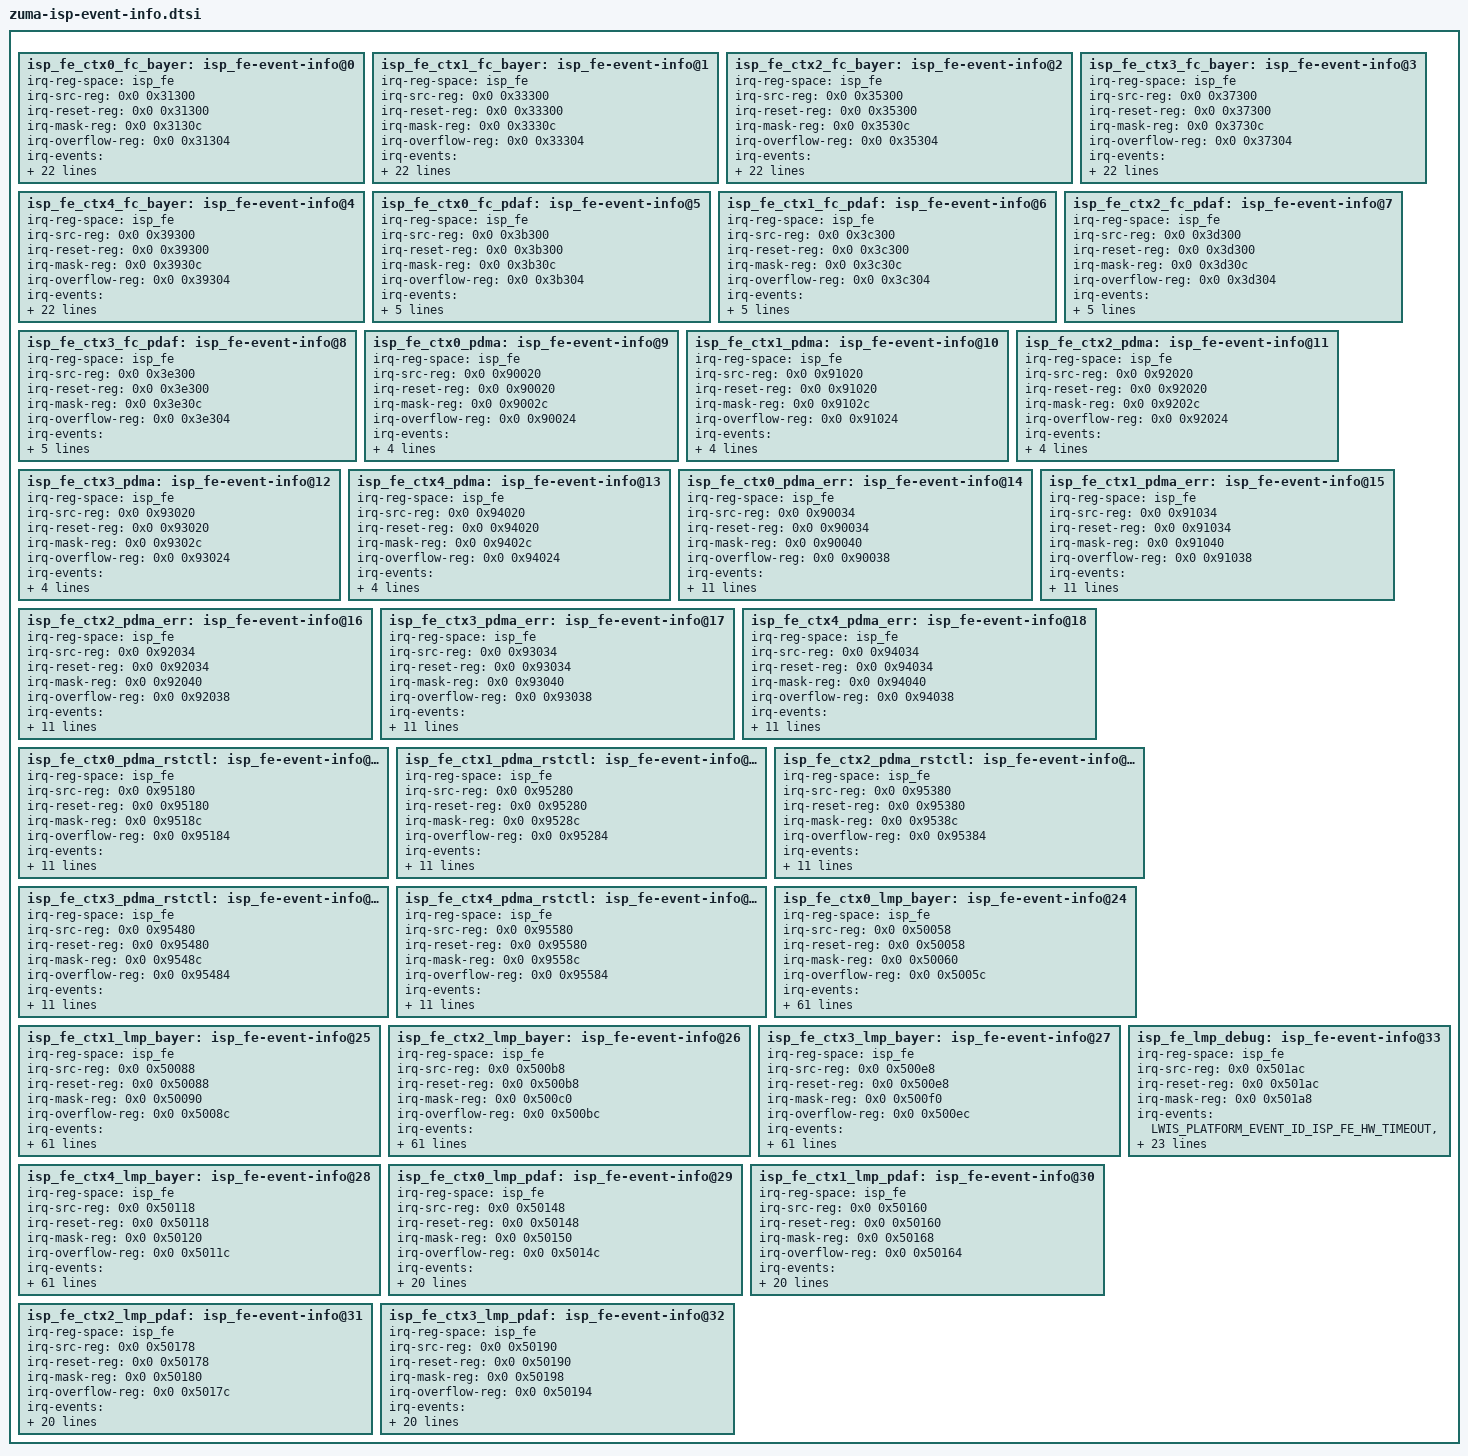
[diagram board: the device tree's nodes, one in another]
// SPDX-License-Identifier: GPL-2.0-only
/*
 * Google ZUMA ISP device tree for interrupt events
 *
 * Copyright 2022 Google LLC.
 */

#include <dt-bindings/lwis/platform/zuma/fc.h>
{
	/* FC bayer pipeline interrupt event definitions */
	isp_fe_ctx0_fc_bayer: isp_fe-event-info@0 {
		irq-reg-space = "isp_fe";
		irq-src-reg = <0x0 0x31300>;
		irq-reset-reg = <0x0 0x31300>;
		irq-mask-reg = <0x0 0x3130c>;
		irq-overflow-reg = <0x0 0x31304>;

		irq-events =
			<LWIS_PLATFORM_EVENT_ID_ISP_FE_CTX0_FC_SOF>,
			<LWIS_PLATFORM_EVENT_ID_ISP_FE_CTX0_FC_EOF>,
			<LWIS_PLATFORM_EVENT_ID_ISP_FE_CTX0_FC_REG_UPDATED>,
			<LWIS_PLATFORM_EVENT_ID_ISP_FE_CTX0_FC_ABORT_START>,
			<LWIS_PLATFORM_EVENT_ID_ISP_FE_CTX0_FC_ABORT_DMA_CMPLT>,
			<LWIS_PLATFORM_EVENT_ID_ISP_FE_CTX0_FC_ABORT_DONE>,
			<LWIS_PLATFORM_EVENT_ID_ISP_FE_CTX0_FC_LATE_CONFIG>,
			<LWIS_PLATFORM_EVENT_ID_ISP_FE_CTX0_FC_ERROR>,
			<LWIS_PLATFORM_EVENT_ID_ISP_FE_CTX0_SPD_WDMA_BUS_ERROR>,
			<LWIS_PLATFORM_EVENT_ID_ISP_FE_CTX0_LMP_IDMA0_BUS_ERROR>,
			<LWIS_PLATFORM_EVENT_ID_ISP_FE_CTX0_LMP_IDMA1_BUS_ERROR>;
		int-reg-bits =
			<ISP_FE_FC_BAYER_CTX0_FC_SOF>,
			<ISP_FE_FC_BAYER_CTX0_FC_EOF>,
			<ISP_FE_FC_BAYER_CTX0_FC_REG_UPDATED>,
			<ISP_FE_FC_BAYER_CTX0_FC_ABORT_START>,
			<ISP_FE_FC_BAYER_CTX0_FC_ABORT_DMA_CMPLT>,
			<ISP_FE_FC_BAYER_CTX0_FC_ABORT_DONE>,
			<ISP_FE_FC_BAYER_CTX0_FC_LATE_CONFIG>,
			<ISP_FE_FC_BAYER_CTX0_FC_ERROR>,
			<ISP_FE_FC_BAYER_CTX0_SPD_WDMA_BUS_ERROR>,
			<ISP_FE_FC_BAYER_CTX0_LMP_IDMA0_BUS_ERROR>,
			<ISP_FE_FC_BAYER_CTX0_LMP_IDMA1_BUS_ERROR>;
	};
	isp_fe_ctx1_fc_bayer: isp_fe-event-info@1 {
		irq-reg-space = "isp_fe";
		irq-src-reg = <0x0 0x33300>;
		irq-reset-reg = <0x0 0x33300>;
		irq-mask-reg = <0x0 0x3330c>;
		irq-overflow-reg = <0x0 0x33304>;

		irq-events =
			<LWIS_PLATFORM_EVENT_ID_ISP_FE_CTX1_FC_SOF>,
			<LWIS_PLATFORM_EVENT_ID_ISP_FE_CTX1_FC_EOF>,
			<LWIS_PLATFORM_EVENT_ID_ISP_FE_CTX1_FC_REG_UPDATED>,
			<LWIS_PLATFORM_EVENT_ID_ISP_FE_CTX1_FC_ABORT_START>,
			<LWIS_PLATFORM_EVENT_ID_ISP_FE_CTX1_FC_ABORT_DMA_CMPLT>,
			<LWIS_PLATFORM_EVENT_ID_ISP_FE_CTX1_FC_ABORT_DONE>,
			<LWIS_PLATFORM_EVENT_ID_ISP_FE_CTX1_FC_LATE_CONFIG>,
			<LWIS_PLATFORM_EVENT_ID_ISP_FE_CTX1_FC_ERROR>,
			<LWIS_PLATFORM_EVENT_ID_ISP_FE_CTX1_SPD_WDMA_BUS_ERROR>,
			<LWIS_PLATFORM_EVENT_ID_ISP_FE_CTX1_LMP_IDMA0_BUS_ERROR>,
			<LWIS_PLATFORM_EVENT_ID_ISP_FE_CTX1_LMP_IDMA1_BUS_ERROR>;
		int-reg-bits =
			<ISP_FE_FC_BAYER_CTX1_FC_SOF>,
			<ISP_FE_FC_BAYER_CTX1_FC_EOF>,
			<ISP_FE_FC_BAYER_CTX1_FC_REG_UPDATED>,
			<ISP_FE_FC_BAYER_CTX1_FC_ABORT_START>,
			<ISP_FE_FC_BAYER_CTX1_FC_ABORT_DMA_CMPLT>,
			<ISP_FE_FC_BAYER_CTX1_FC_ABORT_DONE>,
			<ISP_FE_FC_BAYER_CTX1_FC_LATE_CONFIG>,
			<ISP_FE_FC_BAYER_CTX1_FC_ERROR>,
			<ISP_FE_FC_BAYER_CTX1_SPD_WDMA_BUS_ERROR>,
			<ISP_FE_FC_BAYER_CTX1_LMP_IDMA0_BUS_ERROR>,
			<ISP_FE_FC_BAYER_CTX1_LMP_IDMA1_BUS_ERROR>;
	};
	isp_fe_ctx2_fc_bayer: isp_fe-event-info@2 {
		irq-reg-space = "isp_fe";
		irq-src-reg = <0x0 0x35300>;
		irq-reset-reg = <0x0 0x35300>;
		irq-mask-reg = <0x0 0x3530c>;
		irq-overflow-reg = <0x0 0x35304>;

		irq-events =
			<LWIS_PLATFORM_EVENT_ID_ISP_FE_CTX2_FC_SOF>,
			<LWIS_PLATFORM_EVENT_ID_ISP_FE_CTX2_FC_EOF>,
			<LWIS_PLATFORM_EVENT_ID_ISP_FE_CTX2_FC_REG_UPDATED>,
			<LWIS_PLATFORM_EVENT_ID_ISP_FE_CTX2_FC_ABORT_START>,
			<LWIS_PLATFORM_EVENT_ID_ISP_FE_CTX2_FC_ABORT_DMA_CMPLT>,
			<LWIS_PLATFORM_EVENT_ID_ISP_FE_CTX2_FC_ABORT_DONE>,
			<LWIS_PLATFORM_EVENT_ID_ISP_FE_CTX2_FC_LATE_CONFIG>,
			<LWIS_PLATFORM_EVENT_ID_ISP_FE_CTX2_FC_ERROR>,
			<LWIS_PLATFORM_EVENT_ID_ISP_FE_CTX2_SPD_WDMA_BUS_ERROR>,
			<LWIS_PLATFORM_EVENT_ID_ISP_FE_CTX2_LMP_IDMA0_BUS_ERROR>,
			<LWIS_PLATFORM_EVENT_ID_ISP_FE_CTX2_LMP_IDMA1_BUS_ERROR>;
		int-reg-bits =
			<ISP_FE_FC_BAYER_CTX2_FC_SOF>,
			<ISP_FE_FC_BAYER_CTX2_FC_EOF>,
			<ISP_FE_FC_BAYER_CTX2_FC_REG_UPDATED>,
			<ISP_FE_FC_BAYER_CTX2_FC_ABORT_START>,
			<ISP_FE_FC_BAYER_CTX2_FC_ABORT_DMA_CMPLT>,
			<ISP_FE_FC_BAYER_CTX2_FC_ABORT_DONE>,
			<ISP_FE_FC_BAYER_CTX2_FC_LATE_CONFIG>,
			<ISP_FE_FC_BAYER_CTX2_FC_ERROR>,
			<ISP_FE_FC_BAYER_CTX2_SPD_WDMA_BUS_ERROR>,
			<ISP_FE_FC_BAYER_CTX2_LMP_IDMA0_BUS_ERROR>,
			<ISP_FE_FC_BAYER_CTX2_LMP_IDMA1_BUS_ERROR>;
	};
	isp_fe_ctx3_fc_bayer: isp_fe-event-info@3 {
		irq-reg-space = "isp_fe";
		irq-src-reg = <0x0 0x37300>;
		irq-reset-reg = <0x0 0x37300>;
		irq-mask-reg = <0x0 0x3730c>;
		irq-overflow-reg = <0x0 0x37304>;

		irq-events =
			<LWIS_PLATFORM_EVENT_ID_ISP_FE_CTX3_FC_SOF>,
			<LWIS_PLATFORM_EVENT_ID_ISP_FE_CTX3_FC_EOF>,
			<LWIS_PLATFORM_EVENT_ID_ISP_FE_CTX3_FC_REG_UPDATED>,
			<LWIS_PLATFORM_EVENT_ID_ISP_FE_CTX3_FC_ABORT_START>,
			<LWIS_PLATFORM_EVENT_ID_ISP_FE_CTX3_FC_ABORT_DMA_CMPLT>,
			<LWIS_PLATFORM_EVENT_ID_ISP_FE_CTX3_FC_ABORT_DONE>,
			<LWIS_PLATFORM_EVENT_ID_ISP_FE_CTX3_FC_LATE_CONFIG>,
			<LWIS_PLATFORM_EVENT_ID_ISP_FE_CTX3_FC_ERROR>,
			<LWIS_PLATFORM_EVENT_ID_ISP_FE_CTX3_SPD_WDMA_BUS_ERROR>,
			<LWIS_PLATFORM_EVENT_ID_ISP_FE_CTX3_LMP_IDMA0_BUS_ERROR>,
			<LWIS_PLATFORM_EVENT_ID_ISP_FE_CTX3_LMP_IDMA1_BUS_ERROR>;
		int-reg-bits =
			<ISP_FE_FC_BAYER_CTX3_FC_SOF>,
			<ISP_FE_FC_BAYER_CTX3_FC_EOF>,
			<ISP_FE_FC_BAYER_CTX3_FC_REG_UPDATED>,
			<ISP_FE_FC_BAYER_CTX3_FC_ABORT_START>,
			<ISP_FE_FC_BAYER_CTX3_FC_ABORT_DMA_CMPLT>,
			<ISP_FE_FC_BAYER_CTX3_FC_ABORT_DONE>,
			<ISP_FE_FC_BAYER_CTX3_FC_LATE_CONFIG>,
			<ISP_FE_FC_BAYER_CTX3_FC_ERROR>,
			<ISP_FE_FC_BAYER_CTX3_SPD_WDMA_BUS_ERROR>,
			<ISP_FE_FC_BAYER_CTX3_LMP_IDMA0_BUS_ERROR>,
			<ISP_FE_FC_BAYER_CTX3_LMP_IDMA1_BUS_ERROR>;
	};
	isp_fe_ctx4_fc_bayer: isp_fe-event-info@4 {
		irq-reg-space = "isp_fe";
		irq-src-reg = <0x0 0x39300>;
		irq-reset-reg = <0x0 0x39300>;
		irq-mask-reg = <0x0 0x3930c>;
		irq-overflow-reg = <0x0 0x39304>;

		irq-events =
			<LWIS_PLATFORM_EVENT_ID_ISP_FE_CTX4_FC_SOF>,
			<LWIS_PLATFORM_EVENT_ID_ISP_FE_CTX4_FC_EOF>,
			<LWIS_PLATFORM_EVENT_ID_ISP_FE_CTX4_FC_REG_UPDATED>,
			<LWIS_PLATFORM_EVENT_ID_ISP_FE_CTX4_FC_ABORT_START>,
			<LWIS_PLATFORM_EVENT_ID_ISP_FE_CTX4_FC_ABORT_DMA_CMPLT>,
			<LWIS_PLATFORM_EVENT_ID_ISP_FE_CTX4_FC_ABORT_DONE>,
			<LWIS_PLATFORM_EVENT_ID_ISP_FE_CTX4_FC_LATE_CONFIG>,
			<LWIS_PLATFORM_EVENT_ID_ISP_FE_CTX4_FC_ERROR>,
			<LWIS_PLATFORM_EVENT_ID_ISP_FE_CTX4_SPD_WDMA_BUS_ERROR>,
			<LWIS_PLATFORM_EVENT_ID_ISP_FE_CTX4_LMP_IDMA0_BUS_ERROR>,
			<LWIS_PLATFORM_EVENT_ID_ISP_FE_CTX4_LMP_IDMA1_BUS_ERROR>;
		int-reg-bits =
			<ISP_FE_FC_BAYER_CTX4_FC_SOF>,
			<ISP_FE_FC_BAYER_CTX4_FC_EOF>,
			<ISP_FE_FC_BAYER_CTX4_FC_REG_UPDATED>,
			<ISP_FE_FC_BAYER_CTX4_FC_ABORT_START>,
			<ISP_FE_FC_BAYER_CTX4_FC_ABORT_DMA_CMPLT>,
			<ISP_FE_FC_BAYER_CTX4_FC_ABORT_DONE>,
			<ISP_FE_FC_BAYER_CTX4_FC_LATE_CONFIG>,
			<ISP_FE_FC_BAYER_CTX4_FC_ERROR>,
			<ISP_FE_FC_BAYER_CTX4_SPD_WDMA_BUS_ERROR>,
			<ISP_FE_FC_BAYER_CTX4_LMP_IDMA0_BUS_ERROR>,
			<ISP_FE_FC_BAYER_CTX4_LMP_IDMA1_BUS_ERROR>;
	};
	/* FC pdaf pipeline interrupt event definitions */
	isp_fe_ctx0_fc_pdaf: isp_fe-event-info@5 {
		irq-reg-space = "isp_fe";
		irq-src-reg = <0x0 0x3b300>;
		irq-reset-reg = <0x0 0x3b300>;
		irq-mask-reg = <0x0 0x3b30c>;
		irq-overflow-reg = <0x0 0x3b304>;

		irq-events =
			<LWIS_PLATFORM_EVENT_ID_ISP_FE_CTX0_PDAF_LATE_CONFIG>,
			<LWIS_PLATFORM_EVENT_ID_ISP_FE_CTX0_PDAF_ERROR>;
		int-reg-bits =
			<ISP_FE_FC_PDAF_CTX0_PDAF_LATE_CONFIG>,
			<ISP_FE_FC_PDAF_CTX0_PDAF_ERROR>;
	};
	isp_fe_ctx1_fc_pdaf: isp_fe-event-info@6 {
		irq-reg-space = "isp_fe";
		irq-src-reg = <0x0 0x3c300>;
		irq-reset-reg = <0x0 0x3c300>;
		irq-mask-reg = <0x0 0x3c30c>;
		irq-overflow-reg = <0x0 0x3c304>;

		irq-events =
			<LWIS_PLATFORM_EVENT_ID_ISP_FE_CTX1_PDAF_LATE_CONFIG>,
			<LWIS_PLATFORM_EVENT_ID_ISP_FE_CTX1_PDAF_ERROR>;
		int-reg-bits =
			<ISP_FE_FC_PDAF_CTX1_PDAF_LATE_CONFIG>,
			<ISP_FE_FC_PDAF_CTX1_PDAF_ERROR>;
	};
	isp_fe_ctx2_fc_pdaf: isp_fe-event-info@7 {
		irq-reg-space = "isp_fe";
		irq-src-reg = <0x0 0x3d300>;
		irq-reset-reg = <0x0 0x3d300>;
		irq-mask-reg = <0x0 0x3d30c>;
		irq-overflow-reg = <0x0 0x3d304>;

		irq-events =
			<LWIS_PLATFORM_EVENT_ID_ISP_FE_CTX2_PDAF_LATE_CONFIG>,
			<LWIS_PLATFORM_EVENT_ID_ISP_FE_CTX2_PDAF_ERROR>;
		int-reg-bits =
			<ISP_FE_FC_PDAF_CTX2_PDAF_LATE_CONFIG>,
			<ISP_FE_FC_PDAF_CTX2_PDAF_ERROR>;
	};
	isp_fe_ctx3_fc_pdaf: isp_fe-event-info@8 {
		irq-reg-space = "isp_fe";
		irq-src-reg = <0x0 0x3e300>;
		irq-reset-reg = <0x0 0x3e300>;
		irq-mask-reg = <0x0 0x3e30c>;
		irq-overflow-reg = <0x0 0x3e304>;

		irq-events =
			<LWIS_PLATFORM_EVENT_ID_ISP_FE_CTX3_PDAF_LATE_CONFIG>,
			<LWIS_PLATFORM_EVENT_ID_ISP_FE_CTX3_PDAF_ERROR>;
		int-reg-bits =
			<ISP_FE_FC_PDAF_CTX3_PDAF_LATE_CONFIG>,
			<ISP_FE_FC_PDAF_CTX3_PDAF_ERROR>;
	};
	/* PDMA interrupt event definitions */
	isp_fe_ctx0_pdma: isp_fe-event-info@9 {
		irq-reg-space = "isp_fe";
		irq-src-reg = <0x0 0x90020>;
		irq-reset-reg = <0x0 0x90020>;
		irq-mask-reg = <0x0 0x9002c>;
		irq-overflow-reg = <0x0 0x90024>;

		irq-events =
			<LWIS_PLATFORM_EVENT_ID_ISP_FE_CTX0_IRQ_CMD>,
			<LWIS_PLATFORM_EVENT_ID_ISP_FE_CTX0_ALMOST_EMPTY>;
		int-reg-bits =
			<ISP_FE_PDMA_CTX0_IRQ_CMD>,
			<ISP_FE_PDMA_CTX0_ALMOST_EMPTY>;
	};
	isp_fe_ctx1_pdma: isp_fe-event-info@10 {
		irq-reg-space = "isp_fe";
		irq-src-reg = <0x0 0x91020>;
		irq-reset-reg = <0x0 0x91020>;
		irq-mask-reg = <0x0 0x9102c>;
		irq-overflow-reg = <0x0 0x91024>;

		irq-events =
			<LWIS_PLATFORM_EVENT_ID_ISP_FE_CTX1_IRQ_CMD>,
			<LWIS_PLATFORM_EVENT_ID_ISP_FE_CTX1_ALMOST_EMPTY>;
		int-reg-bits =
			<ISP_FE_PDMA_CTX1_IRQ_CMD>,
			<ISP_FE_PDMA_CTX1_ALMOST_EMPTY>;
	};
	isp_fe_ctx2_pdma: isp_fe-event-info@11 {
		irq-reg-space = "isp_fe";
		irq-src-reg = <0x0 0x92020>;
		irq-reset-reg = <0x0 0x92020>;
		irq-mask-reg = <0x0 0x9202c>;
		irq-overflow-reg = <0x0 0x92024>;

		irq-events =
			<LWIS_PLATFORM_EVENT_ID_ISP_FE_CTX2_IRQ_CMD>,
			<LWIS_PLATFORM_EVENT_ID_ISP_FE_CTX2_ALMOST_EMPTY>;
		int-reg-bits =
			<ISP_FE_PDMA_CTX2_IRQ_CMD>,
			<ISP_FE_PDMA_CTX2_ALMOST_EMPTY>;
	};
	isp_fe_ctx3_pdma: isp_fe-event-info@12 {
		irq-reg-space = "isp_fe";
		irq-src-reg = <0x0 0x93020>;
		irq-reset-reg = <0x0 0x93020>;
		irq-mask-reg = <0x0 0x9302c>;
		irq-overflow-reg = <0x0 0x93024>;

		irq-events =
			<LWIS_PLATFORM_EVENT_ID_ISP_FE_CTX3_IRQ_CMD>,
			<LWIS_PLATFORM_EVENT_ID_ISP_FE_CTX3_ALMOST_EMPTY>;
		int-reg-bits =
			<ISP_FE_PDMA_CTX3_IRQ_CMD>,
			<ISP_FE_PDMA_CTX3_ALMOST_EMPTY>;
	};
	isp_fe_ctx4_pdma: isp_fe-event-info@13 {
		irq-reg-space = "isp_fe";
		irq-src-reg = <0x0 0x94020>;
		irq-reset-reg = <0x0 0x94020>;
		irq-mask-reg = <0x0 0x9402c>;
		irq-overflow-reg = <0x0 0x94024>;

		irq-events =
			<LWIS_PLATFORM_EVENT_ID_ISP_FE_CTX4_IRQ_CMD>,
			<LWIS_PLATFORM_EVENT_ID_ISP_FE_CTX4_ALMOST_EMPTY>;
		int-reg-bits =
			<ISP_FE_PDMA_CTX4_IRQ_CMD>,
			<ISP_FE_PDMA_CTX4_ALMOST_EMPTY>;
	};
	/* PDMA error interrupt event definitions */
	isp_fe_ctx0_pdma_err: isp_fe-event-info@14 {
		irq-reg-space = "isp_fe";
		irq-src-reg = <0x0 0x90034>;
		irq-reset-reg = <0x0 0x90034>;
		irq-mask-reg = <0x0 0x90040>;
		irq-overflow-reg = <0x0 0x90038>;

		irq-events =
			<LWIS_PLATFORM_EVENT_ID_ISP_FE_CTX0_MEM_BUS_ERR>,
			<LWIS_PLATFORM_EVENT_ID_ISP_FE_CTX0_CSR_BUS_ERR>,
			<LWIS_PLATFORM_EVENT_ID_ISP_FE_CTX0_ILLEGAL_CMD>,
			<LWIS_PLATFORM_EVENT_ID_ISP_FE_CTX0_RECUR_INDIR_CMD>,
			<LWIS_PLATFORM_EVENT_ID_ISP_FE_CTX0_CMD_SIZE_MISMATCH>;
		int-reg-bits =
			<ISP_FE_PDMA_ERR_CTX0_MEM_BUS_ERR>,
			<ISP_FE_PDMA_ERR_CTX0_CSR_BUS_ERR>,
			<ISP_FE_PDMA_ERR_CTX0_ILLEGAL_CMD>,
			<ISP_FE_PDMA_ERR_CTX0_RECUR_INDIR_CMD>,
			<ISP_FE_PDMA_ERR_CTX0_CMD_SIZE_MISMATCH>;
	};
	isp_fe_ctx1_pdma_err: isp_fe-event-info@15 {
		irq-reg-space = "isp_fe";
		irq-src-reg = <0x0 0x91034>;
		irq-reset-reg = <0x0 0x91034>;
		irq-mask-reg = <0x0 0x91040>;
		irq-overflow-reg = <0x0 0x91038>;

		irq-events =
			<LWIS_PLATFORM_EVENT_ID_ISP_FE_CTX1_MEM_BUS_ERR>,
			<LWIS_PLATFORM_EVENT_ID_ISP_FE_CTX1_CSR_BUS_ERR>,
			<LWIS_PLATFORM_EVENT_ID_ISP_FE_CTX1_ILLEGAL_CMD>,
			<LWIS_PLATFORM_EVENT_ID_ISP_FE_CTX1_RECUR_INDIR_CMD>,
			<LWIS_PLATFORM_EVENT_ID_ISP_FE_CTX1_CMD_SIZE_MISMATCH>;
		int-reg-bits =
			<ISP_FE_PDMA_ERR_CTX1_MEM_BUS_ERR>,
			<ISP_FE_PDMA_ERR_CTX1_CSR_BUS_ERR>,
			<ISP_FE_PDMA_ERR_CTX1_ILLEGAL_CMD>,
			<ISP_FE_PDMA_ERR_CTX1_RECUR_INDIR_CMD>,
			<ISP_FE_PDMA_ERR_CTX1_CMD_SIZE_MISMATCH>;
	};
	isp_fe_ctx2_pdma_err: isp_fe-event-info@16 {
		irq-reg-space = "isp_fe";
		irq-src-reg = <0x0 0x92034>;
		irq-reset-reg = <0x0 0x92034>;
		irq-mask-reg = <0x0 0x92040>;
		irq-overflow-reg = <0x0 0x92038>;

		irq-events =
			<LWIS_PLATFORM_EVENT_ID_ISP_FE_CTX2_MEM_BUS_ERR>,
			<LWIS_PLATFORM_EVENT_ID_ISP_FE_CTX2_CSR_BUS_ERR>,
			<LWIS_PLATFORM_EVENT_ID_ISP_FE_CTX2_ILLEGAL_CMD>,
			<LWIS_PLATFORM_EVENT_ID_ISP_FE_CTX2_RECUR_INDIR_CMD>,
			<LWIS_PLATFORM_EVENT_ID_ISP_FE_CTX2_CMD_SIZE_MISMATCH>;
		int-reg-bits =
			<ISP_FE_PDMA_ERR_CTX2_MEM_BUS_ERR>,
			<ISP_FE_PDMA_ERR_CTX2_CSR_BUS_ERR>,
			<ISP_FE_PDMA_ERR_CTX2_ILLEGAL_CMD>,
			<ISP_FE_PDMA_ERR_CTX2_RECUR_INDIR_CMD>,
			<ISP_FE_PDMA_ERR_CTX2_CMD_SIZE_MISMATCH>;
	};
	isp_fe_ctx3_pdma_err: isp_fe-event-info@17 {
		irq-reg-space = "isp_fe";
		irq-src-reg = <0x0 0x93034>;
		irq-reset-reg = <0x0 0x93034>;
		irq-mask-reg = <0x0 0x93040>;
		irq-overflow-reg = <0x0 0x93038>;

		irq-events =
			<LWIS_PLATFORM_EVENT_ID_ISP_FE_CTX3_MEM_BUS_ERR>,
			<LWIS_PLATFORM_EVENT_ID_ISP_FE_CTX3_CSR_BUS_ERR>,
			<LWIS_PLATFORM_EVENT_ID_ISP_FE_CTX3_ILLEGAL_CMD>,
			<LWIS_PLATFORM_EVENT_ID_ISP_FE_CTX3_RECUR_INDIR_CMD>,
			<LWIS_PLATFORM_EVENT_ID_ISP_FE_CTX3_CMD_SIZE_MISMATCH>;
		int-reg-bits =
			<ISP_FE_PDMA_ERR_CTX3_MEM_BUS_ERR>,
			<ISP_FE_PDMA_ERR_CTX3_CSR_BUS_ERR>,
			<ISP_FE_PDMA_ERR_CTX3_ILLEGAL_CMD>,
			<ISP_FE_PDMA_ERR_CTX3_RECUR_INDIR_CMD>,
			<ISP_FE_PDMA_ERR_CTX3_CMD_SIZE_MISMATCH>;
	};
	isp_fe_ctx4_pdma_err: isp_fe-event-info@18 {
		irq-reg-space = "isp_fe";
		irq-src-reg = <0x0 0x94034>;
		irq-reset-reg = <0x0 0x94034>;
		irq-mask-reg = <0x0 0x94040>;
		irq-overflow-reg = <0x0 0x94038>;

		irq-events =
			<LWIS_PLATFORM_EVENT_ID_ISP_FE_CTX4_MEM_BUS_ERR>,
			<LWIS_PLATFORM_EVENT_ID_ISP_FE_CTX4_CSR_BUS_ERR>,
			<LWIS_PLATFORM_EVENT_ID_ISP_FE_CTX4_ILLEGAL_CMD>,
			<LWIS_PLATFORM_EVENT_ID_ISP_FE_CTX4_RECUR_INDIR_CMD>,
			<LWIS_PLATFORM_EVENT_ID_ISP_FE_CTX4_CMD_SIZE_MISMATCH>;
		int-reg-bits =
			<ISP_FE_PDMA_ERR_CTX4_MEM_BUS_ERR>,
			<ISP_FE_PDMA_ERR_CTX4_CSR_BUS_ERR>,
			<ISP_FE_PDMA_ERR_CTX4_ILLEGAL_CMD>,
			<ISP_FE_PDMA_ERR_CTX4_RECUR_INDIR_CMD>,
			<ISP_FE_PDMA_ERR_CTX4_CMD_SIZE_MISMATCH>;
	};
	/* PDMA Wrap reset controller interrupt event definitions */
	isp_fe_ctx0_pdma_rstctl: isp_fe-event-info@19 {
		irq-reg-space = "isp_fe";
		irq-src-reg = <0x0 0x95180>;
		irq-reset-reg = <0x0 0x95180>;
		irq-mask-reg = <0x0 0x9518c>;
		irq-overflow-reg = <0x0 0x95184>;

		irq-events =
			<LWIS_PLATFORM_EVENT_ID_ISP_FE_CTX0_SW_RESET_DONE>,
			<LWIS_PLATFORM_EVENT_ID_ISP_FE_CTX0_INPUT_FLUSH_DONE>,
			<LWIS_PLATFORM_EVENT_ID_ISP_FE_CTX0_SW_MODE>,
			<LWIS_PLATFORM_EVENT_ID_ISP_FE_CTX0_APB_GKP_ERR>,
			<LWIS_PLATFORM_EVENT_ID_ISP_FE_CTX0_AXI_GKP_ERR>;
		int-reg-bits =
			<ISP_FE_PDMA_RSTCTL_CTX0_SW_RESET_DONE>,
			<ISP_FE_PDMA_RSTCTL_CTX0_INPUT_FLUSH_DONE>,
			<ISP_FE_PDMA_RSTCTL_CTX0_SW_MODE>,
			<ISP_FE_PDMA_RSTCTL_CTX0_APB_GKP_ERR>,
			<ISP_FE_PDMA_RSTCTL_CTX0_AXI_GKP_ERR>;
	};
	isp_fe_ctx1_pdma_rstctl: isp_fe-event-info@20 {
		irq-reg-space = "isp_fe";
		irq-src-reg = <0x0 0x95280>;
		irq-reset-reg = <0x0 0x95280>;
		irq-mask-reg = <0x0 0x9528c>;
		irq-overflow-reg = <0x0 0x95284>;

		irq-events =
			<LWIS_PLATFORM_EVENT_ID_ISP_FE_CTX1_SW_RESET_DONE>,
			<LWIS_PLATFORM_EVENT_ID_ISP_FE_CTX1_INPUT_FLUSH_DONE>,
			<LWIS_PLATFORM_EVENT_ID_ISP_FE_CTX1_SW_MODE>,
			<LWIS_PLATFORM_EVENT_ID_ISP_FE_CTX1_APB_GKP_ERR>,
			<LWIS_PLATFORM_EVENT_ID_ISP_FE_CTX1_AXI_GKP_ERR>;
		int-reg-bits =
			<ISP_FE_PDMA_RSTCTL_CTX1_SW_RESET_DONE>,
			<ISP_FE_PDMA_RSTCTL_CTX1_INPUT_FLUSH_DONE>,
			<ISP_FE_PDMA_RSTCTL_CTX1_SW_MODE>,
			<ISP_FE_PDMA_RSTCTL_CTX1_APB_GKP_ERR>,
			<ISP_FE_PDMA_RSTCTL_CTX1_AXI_GKP_ERR>;
	};
	isp_fe_ctx2_pdma_rstctl: isp_fe-event-info@21 {
		irq-reg-space = "isp_fe";
		irq-src-reg = <0x0 0x95380>;
		irq-reset-reg = <0x0 0x95380>;
		irq-mask-reg = <0x0 0x9538c>;
		irq-overflow-reg = <0x0 0x95384>;

		irq-events =
			<LWIS_PLATFORM_EVENT_ID_ISP_FE_CTX2_SW_RESET_DONE>,
			<LWIS_PLATFORM_EVENT_ID_ISP_FE_CTX2_INPUT_FLUSH_DONE>,
			<LWIS_PLATFORM_EVENT_ID_ISP_FE_CTX2_SW_MODE>,
			<LWIS_PLATFORM_EVENT_ID_ISP_FE_CTX2_APB_GKP_ERR>,
			<LWIS_PLATFORM_EVENT_ID_ISP_FE_CTX2_AXI_GKP_ERR>;
		int-reg-bits =
			<ISP_FE_PDMA_RSTCTL_CTX2_SW_RESET_DONE>,
			<ISP_FE_PDMA_RSTCTL_CTX2_INPUT_FLUSH_DONE>,
			<ISP_FE_PDMA_RSTCTL_CTX2_SW_MODE>,
			<ISP_FE_PDMA_RSTCTL_CTX2_APB_GKP_ERR>,
			<ISP_FE_PDMA_RSTCTL_CTX2_AXI_GKP_ERR>;
	};
	isp_fe_ctx3_pdma_rstctl: isp_fe-event-info@22 {
		irq-reg-space = "isp_fe";
		irq-src-reg = <0x0 0x95480>;
		irq-reset-reg = <0x0 0x95480>;
		irq-mask-reg = <0x0 0x9548c>;
		irq-overflow-reg = <0x0 0x95484>;

		irq-events =
			<LWIS_PLATFORM_EVENT_ID_ISP_FE_CTX3_SW_RESET_DONE>,
			<LWIS_PLATFORM_EVENT_ID_ISP_FE_CTX3_INPUT_FLUSH_DONE>,
			<LWIS_PLATFORM_EVENT_ID_ISP_FE_CTX3_SW_MODE>,
			<LWIS_PLATFORM_EVENT_ID_ISP_FE_CTX3_APB_GKP_ERR>,
			<LWIS_PLATFORM_EVENT_ID_ISP_FE_CTX3_AXI_GKP_ERR>;
		int-reg-bits =
			<ISP_FE_PDMA_RSTCTL_CTX3_SW_RESET_DONE>,
			<ISP_FE_PDMA_RSTCTL_CTX3_INPUT_FLUSH_DONE>,
			<ISP_FE_PDMA_RSTCTL_CTX3_SW_MODE>,
			<ISP_FE_PDMA_RSTCTL_CTX3_APB_GKP_ERR>,
			<ISP_FE_PDMA_RSTCTL_CTX3_AXI_GKP_ERR>;
	};
	isp_fe_ctx4_pdma_rstctl: isp_fe-event-info@23 {
		irq-reg-space = "isp_fe";
		irq-src-reg = <0x0 0x95580>;
		irq-reset-reg = <0x0 0x95580>;
		irq-mask-reg = <0x0 0x9558c>;
		irq-overflow-reg = <0x0 0x95584>;

		irq-events =
			<LWIS_PLATFORM_EVENT_ID_ISP_FE_CTX4_SW_RESET_DONE>,
			<LWIS_PLATFORM_EVENT_ID_ISP_FE_CTX4_INPUT_FLUSH_DONE>,
			<LWIS_PLATFORM_EVENT_ID_ISP_FE_CTX4_SW_MODE>,
			<LWIS_PLATFORM_EVENT_ID_ISP_FE_CTX4_APB_GKP_ERR>,
			<LWIS_PLATFORM_EVENT_ID_ISP_FE_CTX4_AXI_GKP_ERR>;
		int-reg-bits =
			<ISP_FE_PDMA_RSTCTL_CTX4_SW_RESET_DONE>,
			<ISP_FE_PDMA_RSTCTL_CTX4_INPUT_FLUSH_DONE>,
			<ISP_FE_PDMA_RSTCTL_CTX4_SW_MODE>,
			<ISP_FE_PDMA_RSTCTL_CTX4_APB_GKP_ERR>,
			<ISP_FE_PDMA_RSTCTL_CTX4_AXI_GKP_ERR>;
	};
	/* LMP bayer pipeline interrupt event definitions */
	isp_fe_ctx0_lmp_bayer: isp_fe-event-info@24 {
		irq-reg-space = "isp_fe";
		irq-src-reg = <0x0 0x50058>;
		irq-reset-reg = <0x0 0x50058>;
		irq-mask-reg = <0x0 0x50060>;
		irq-overflow-reg = <0x0 0x5005c>;

		irq-events =
			<LWIS_PLATFORM_EVENT_ID_ISP_FE_CTX0_REGISTER_UPDATE>,
			<LWIS_PLATFORM_EVENT_ID_ISP_FE_CTX0_EOF>,
			<LWIS_PLATFORM_EVENT_ID_ISP_FE_CTX0_END_OF_BATCH>,
			<LWIS_PLATFORM_EVENT_ID_ISP_FE_CTX0_FE_LMP_ERROR>,
			<LWIS_PLATFORM_EVENT_ID_ISP_FE_CTX0_CDAF_PRIMARY>,
			<LWIS_PLATFORM_EVENT_ID_ISP_FE_CTX0_CDAF_WINDOWS>,
			<LWIS_PLATFORM_EVENT_ID_ISP_FE_CTX0_PRE_LSC_AE_STATS>,
			<LWIS_PLATFORM_EVENT_ID_ISP_FE_CTX0_AWB_STATS>,
			<LWIS_PLATFORM_EVENT_ID_ISP_FE_CTX0_LSC_STATS>,
			<LWIS_PLATFORM_EVENT_ID_ISP_FE_CTX0_FLICKER_STATS>,
			<LWIS_PLATFORM_EVENT_ID_ISP_FE_CTX0_HISTOGRAM0>,
			<LWIS_PLATFORM_EVENT_ID_ISP_FE_CTX0_HISTOGRAM1>,
			<LWIS_PLATFORM_EVENT_ID_ISP_FE_CTX0_HISTOGRAM2>,
			<LWIS_PLATFORM_EVENT_ID_ISP_FE_CTX0_POST_LSC_AE_STATS>,
			<LWIS_PLATFORM_EVENT_ID_ISP_FE_CTX0_MOTION_METERING>,
			<LWIS_PLATFORM_EVENT_ID_ISP_FE_CTX0_BAYER0_WDMA>,
			<LWIS_PLATFORM_EVENT_ID_ISP_FE_CTX0_BAYER1_WDMA>,
			<LWIS_PLATFORM_EVENT_ID_ISP_FE_CTX0_LINEAR_RGB_OUTPUT>,
			<LWIS_PLATFORM_EVENT_ID_ISP_FE_CTX0_ML_OUTPUT0>,
			<LWIS_PLATFORM_EVENT_ID_ISP_FE_CTX0_ML_OUTPUT1>,
			<LWIS_PLATFORM_EVENT_ID_ISP_FE_CTX0_ML_OUTPUT2>,
			<LWIS_PLATFORM_EVENT_ID_ISP_FE_CTX0_TNR_PYRAMID>,
			<LWIS_PLATFORM_EVENT_ID_ISP_FE_CTX0_MERGE1>,
			<LWIS_PLATFORM_EVENT_ID_ISP_FE_CTX0_MERGE2>,
			<LWIS_PLATFORM_EVENT_ID_ISP_FE_CTX0_MERGE3>,
			<LWIS_PLATFORM_EVENT_ID_ISP_FE_CTX0_MERGE4>,
			<LWIS_PLATFORM_EVENT_ID_ISP_FE_CTX0_MERGE5>,
			<LWIS_PLATFORM_EVENT_ID_ISP_FE_CTX0_MERGE6>,
			<LWIS_PLATFORM_EVENT_ID_ISP_FE_CTX0_LMP_BUS_ERROR>,
			<LWIS_PLATFORM_EVENT_ID_ISP_FE_CTX0_SOF>;
		int-reg-bits =
			<ISP_FE_LMP_BAYER_CTX0_REGISTER_UPDATE>,
			<ISP_FE_LMP_BAYER_CTX0_EOF>,
			<ISP_FE_LMP_BAYER_CTX0_END_OF_BATCH>,
			<ISP_FE_LMP_BAYER_CTX0_FE_LMP_ERROR>,
			<ISP_FE_LMP_BAYER_CTX0_CDAF_PRIMARY>,
			<ISP_FE_LMP_BAYER_CTX0_CDAF_WINDOWS>,
			<ISP_FE_LMP_BAYER_CTX0_PRE_LSC_AE_STATS>,
			<ISP_FE_LMP_BAYER_CTX0_AWB_STATS>,
			<ISP_FE_LMP_BAYER_CTX0_LSC_STATS>,
			<ISP_FE_LMP_BAYER_CTX0_FLICKER_STATS>,
			<ISP_FE_LMP_BAYER_CTX0_HISTOGRAM0>,
			<ISP_FE_LMP_BAYER_CTX0_HISTOGRAM1>,
			<ISP_FE_LMP_BAYER_CTX0_HISTOGRAM2>,
			<ISP_FE_LMP_BAYER_CTX0_POST_LSC_AE_STATS>,
			<ISP_FE_LMP_BAYER_CTX0_MOTION_METERING>,
			<ISP_FE_LMP_BAYER_CTX0_BAYER0_WDMA>,
			<ISP_FE_LMP_BAYER_CTX0_BAYER1_WDMA>,
			<ISP_FE_LMP_BAYER_CTX0_LINEAR_RGB_OUTPUT>,
			<ISP_FE_LMP_BAYER_CTX0_ML_OUTPUT0>,
			<ISP_FE_LMP_BAYER_CTX0_ML_OUTPUT1>,
			<ISP_FE_LMP_BAYER_CTX0_ML_OUTPUT2>,
			<ISP_FE_LMP_BAYER_CTX0_TNR_PYRAMID>,
			<ISP_FE_LMP_BAYER_CTX0_MERGE1>,
			<ISP_FE_LMP_BAYER_CTX0_MERGE2>,
			<ISP_FE_LMP_BAYER_CTX0_MERGE3>,
			<ISP_FE_LMP_BAYER_CTX0_MERGE4>,
			<ISP_FE_LMP_BAYER_CTX0_MERGE5>,
			<ISP_FE_LMP_BAYER_CTX0_MERGE6>,
			<ISP_FE_LMP_BAYER_CTX0_LMP_BUS_ERROR>,
			<ISP_FE_LMP_BAYER_CTX0_SOF>;
	};
	isp_fe_ctx1_lmp_bayer: isp_fe-event-info@25 {
		irq-reg-space = "isp_fe";
		irq-src-reg = <0x0 0x50088>;
		irq-reset-reg = <0x0 0x50088>;
		irq-mask-reg = <0x0 0x50090>;
		irq-overflow-reg = <0x0 0x5008c>;

		irq-events =
			<LWIS_PLATFORM_EVENT_ID_ISP_FE_CTX1_REGISTER_UPDATE>,
			<LWIS_PLATFORM_EVENT_ID_ISP_FE_CTX1_EOF>,
			<LWIS_PLATFORM_EVENT_ID_ISP_FE_CTX1_END_OF_BATCH>,
			<LWIS_PLATFORM_EVENT_ID_ISP_FE_CTX1_FE_LMP_ERROR>,
			<LWIS_PLATFORM_EVENT_ID_ISP_FE_CTX1_CDAF_PRIMARY>,
			<LWIS_PLATFORM_EVENT_ID_ISP_FE_CTX1_CDAF_WINDOWS>,
			<LWIS_PLATFORM_EVENT_ID_ISP_FE_CTX1_PRE_LSC_AE_STATS>,
			<LWIS_PLATFORM_EVENT_ID_ISP_FE_CTX1_AWB_STATS>,
			<LWIS_PLATFORM_EVENT_ID_ISP_FE_CTX1_LSC_STATS>,
			<LWIS_PLATFORM_EVENT_ID_ISP_FE_CTX1_FLICKER_STATS>,
			<LWIS_PLATFORM_EVENT_ID_ISP_FE_CTX1_HISTOGRAM0>,
			<LWIS_PLATFORM_EVENT_ID_ISP_FE_CTX1_HISTOGRAM1>,
			<LWIS_PLATFORM_EVENT_ID_ISP_FE_CTX1_HISTOGRAM2>,
			<LWIS_PLATFORM_EVENT_ID_ISP_FE_CTX1_POST_LSC_AE_STATS>,
			<LWIS_PLATFORM_EVENT_ID_ISP_FE_CTX1_MOTION_METERING>,
			<LWIS_PLATFORM_EVENT_ID_ISP_FE_CTX1_BAYER0_WDMA>,
			<LWIS_PLATFORM_EVENT_ID_ISP_FE_CTX1_BAYER1_WDMA>,
			<LWIS_PLATFORM_EVENT_ID_ISP_FE_CTX1_LINEAR_RGB_OUTPUT>,
			<LWIS_PLATFORM_EVENT_ID_ISP_FE_CTX1_ML_OUTPUT0>,
			<LWIS_PLATFORM_EVENT_ID_ISP_FE_CTX1_ML_OUTPUT1>,
			<LWIS_PLATFORM_EVENT_ID_ISP_FE_CTX1_ML_OUTPUT2>,
			<LWIS_PLATFORM_EVENT_ID_ISP_FE_CTX1_TNR_PYRAMID>,
			<LWIS_PLATFORM_EVENT_ID_ISP_FE_CTX1_MERGE1>,
			<LWIS_PLATFORM_EVENT_ID_ISP_FE_CTX1_MERGE2>,
			<LWIS_PLATFORM_EVENT_ID_ISP_FE_CTX1_MERGE3>,
			<LWIS_PLATFORM_EVENT_ID_ISP_FE_CTX1_MERGE4>,
			<LWIS_PLATFORM_EVENT_ID_ISP_FE_CTX1_MERGE5>,
			<LWIS_PLATFORM_EVENT_ID_ISP_FE_CTX1_MERGE6>,
			<LWIS_PLATFORM_EVENT_ID_ISP_FE_CTX1_LMP_BUS_ERROR>,
			<LWIS_PLATFORM_EVENT_ID_ISP_FE_CTX1_SOF>;
		int-reg-bits =
			<ISP_FE_LMP_BAYER_CTX1_REGISTER_UPDATE>,
			<ISP_FE_LMP_BAYER_CTX1_EOF>,
			<ISP_FE_LMP_BAYER_CTX1_END_OF_BATCH>,
			<ISP_FE_LMP_BAYER_CTX1_FE_LMP_ERROR>,
			<ISP_FE_LMP_BAYER_CTX1_CDAF_PRIMARY>,
			<ISP_FE_LMP_BAYER_CTX1_CDAF_WINDOWS>,
			<ISP_FE_LMP_BAYER_CTX1_PRE_LSC_AE_STATS>,
			<ISP_FE_LMP_BAYER_CTX1_AWB_STATS>,
			<ISP_FE_LMP_BAYER_CTX1_LSC_STATS>,
			<ISP_FE_LMP_BAYER_CTX1_FLICKER_STATS>,
			<ISP_FE_LMP_BAYER_CTX1_HISTOGRAM0>,
			<ISP_FE_LMP_BAYER_CTX1_HISTOGRAM1>,
			<ISP_FE_LMP_BAYER_CTX1_HISTOGRAM2>,
			<ISP_FE_LMP_BAYER_CTX1_POST_LSC_AE_STATS>,
			<ISP_FE_LMP_BAYER_CTX1_MOTION_METERING>,
			<ISP_FE_LMP_BAYER_CTX1_BAYER0_WDMA>,
			<ISP_FE_LMP_BAYER_CTX1_BAYER1_WDMA>,
			<ISP_FE_LMP_BAYER_CTX1_LINEAR_RGB_OUTPUT>,
			<ISP_FE_LMP_BAYER_CTX1_ML_OUTPUT0>,
			<ISP_FE_LMP_BAYER_CTX1_ML_OUTPUT1>,
			<ISP_FE_LMP_BAYER_CTX1_ML_OUTPUT2>,
			<ISP_FE_LMP_BAYER_CTX1_TNR_PYRAMID>,
			<ISP_FE_LMP_BAYER_CTX1_MERGE1>,
			<ISP_FE_LMP_BAYER_CTX1_MERGE2>,
			<ISP_FE_LMP_BAYER_CTX1_MERGE3>,
			<ISP_FE_LMP_BAYER_CTX1_MERGE4>,
			<ISP_FE_LMP_BAYER_CTX1_MERGE5>,
			<ISP_FE_LMP_BAYER_CTX1_MERGE6>,
			<ISP_FE_LMP_BAYER_CTX1_LMP_BUS_ERROR>,
			<ISP_FE_LMP_BAYER_CTX1_SOF>;
	};
	isp_fe_ctx2_lmp_bayer: isp_fe-event-info@26 {
		irq-reg-space = "isp_fe";
		irq-src-reg = <0x0 0x500b8>;
		irq-reset-reg = <0x0 0x500b8>;
		irq-mask-reg = <0x0 0x500c0>;
		irq-overflow-reg = <0x0 0x500bc>;

		irq-events =
			<LWIS_PLATFORM_EVENT_ID_ISP_FE_CTX2_REGISTER_UPDATE>,
			<LWIS_PLATFORM_EVENT_ID_ISP_FE_CTX2_EOF>,
			<LWIS_PLATFORM_EVENT_ID_ISP_FE_CTX2_END_OF_BATCH>,
			<LWIS_PLATFORM_EVENT_ID_ISP_FE_CTX2_FE_LMP_ERROR>,
			<LWIS_PLATFORM_EVENT_ID_ISP_FE_CTX2_CDAF_PRIMARY>,
			<LWIS_PLATFORM_EVENT_ID_ISP_FE_CTX2_CDAF_WINDOWS>,
			<LWIS_PLATFORM_EVENT_ID_ISP_FE_CTX2_PRE_LSC_AE_STATS>,
			<LWIS_PLATFORM_EVENT_ID_ISP_FE_CTX2_AWB_STATS>,
			<LWIS_PLATFORM_EVENT_ID_ISP_FE_CTX2_LSC_STATS>,
			<LWIS_PLATFORM_EVENT_ID_ISP_FE_CTX2_FLICKER_STATS>,
			<LWIS_PLATFORM_EVENT_ID_ISP_FE_CTX2_HISTOGRAM0>,
			<LWIS_PLATFORM_EVENT_ID_ISP_FE_CTX2_HISTOGRAM1>,
			<LWIS_PLATFORM_EVENT_ID_ISP_FE_CTX2_HISTOGRAM2>,
			<LWIS_PLATFORM_EVENT_ID_ISP_FE_CTX2_POST_LSC_AE_STATS>,
			<LWIS_PLATFORM_EVENT_ID_ISP_FE_CTX2_MOTION_METERING>,
			<LWIS_PLATFORM_EVENT_ID_ISP_FE_CTX2_BAYER0_WDMA>,
			<LWIS_PLATFORM_EVENT_ID_ISP_FE_CTX2_BAYER1_WDMA>,
			<LWIS_PLATFORM_EVENT_ID_ISP_FE_CTX2_LINEAR_RGB_OUTPUT>,
			<LWIS_PLATFORM_EVENT_ID_ISP_FE_CTX2_ML_OUTPUT0>,
			<LWIS_PLATFORM_EVENT_ID_ISP_FE_CTX2_ML_OUTPUT1>,
			<LWIS_PLATFORM_EVENT_ID_ISP_FE_CTX2_ML_OUTPUT2>,
			<LWIS_PLATFORM_EVENT_ID_ISP_FE_CTX2_TNR_PYRAMID>,
			<LWIS_PLATFORM_EVENT_ID_ISP_FE_CTX2_MERGE1>,
			<LWIS_PLATFORM_EVENT_ID_ISP_FE_CTX2_MERGE2>,
			<LWIS_PLATFORM_EVENT_ID_ISP_FE_CTX2_MERGE3>,
			<LWIS_PLATFORM_EVENT_ID_ISP_FE_CTX2_MERGE4>,
			<LWIS_PLATFORM_EVENT_ID_ISP_FE_CTX2_MERGE5>,
			<LWIS_PLATFORM_EVENT_ID_ISP_FE_CTX2_MERGE6>,
			<LWIS_PLATFORM_EVENT_ID_ISP_FE_CTX2_LMP_BUS_ERROR>,
			<LWIS_PLATFORM_EVENT_ID_ISP_FE_CTX2_SOF>;
		int-reg-bits =
			<ISP_FE_LMP_BAYER_CTX2_REGISTER_UPDATE>,
			<ISP_FE_LMP_BAYER_CTX2_EOF>,
			<ISP_FE_LMP_BAYER_CTX2_END_OF_BATCH>,
			<ISP_FE_LMP_BAYER_CTX2_FE_LMP_ERROR>,
			<ISP_FE_LMP_BAYER_CTX2_CDAF_PRIMARY>,
			<ISP_FE_LMP_BAYER_CTX2_CDAF_WINDOWS>,
			<ISP_FE_LMP_BAYER_CTX2_PRE_LSC_AE_STATS>,
			<ISP_FE_LMP_BAYER_CTX2_AWB_STATS>,
			<ISP_FE_LMP_BAYER_CTX2_LSC_STATS>,
			<ISP_FE_LMP_BAYER_CTX2_FLICKER_STATS>,
			<ISP_FE_LMP_BAYER_CTX2_HISTOGRAM0>,
			<ISP_FE_LMP_BAYER_CTX2_HISTOGRAM1>,
			<ISP_FE_LMP_BAYER_CTX2_HISTOGRAM2>,
			<ISP_FE_LMP_BAYER_CTX2_POST_LSC_AE_STATS>,
			<ISP_FE_LMP_BAYER_CTX2_MOTION_METERING>,
			<ISP_FE_LMP_BAYER_CTX2_BAYER0_WDMA>,
			<ISP_FE_LMP_BAYER_CTX2_BAYER1_WDMA>,
			<ISP_FE_LMP_BAYER_CTX2_LINEAR_RGB_OUTPUT>,
			<ISP_FE_LMP_BAYER_CTX2_ML_OUTPUT0>,
			<ISP_FE_LMP_BAYER_CTX2_ML_OUTPUT1>,
			<ISP_FE_LMP_BAYER_CTX2_ML_OUTPUT2>,
			<ISP_FE_LMP_BAYER_CTX2_TNR_PYRAMID>,
			<ISP_FE_LMP_BAYER_CTX2_MERGE1>,
			<ISP_FE_LMP_BAYER_CTX2_MERGE2>,
			<ISP_FE_LMP_BAYER_CTX2_MERGE3>,
			<ISP_FE_LMP_BAYER_CTX2_MERGE4>,
			<ISP_FE_LMP_BAYER_CTX2_MERGE5>,
			<ISP_FE_LMP_BAYER_CTX2_MERGE6>,
			<ISP_FE_LMP_BAYER_CTX2_LMP_BUS_ERROR>,
			<ISP_FE_LMP_BAYER_CTX2_SOF>;
	};
	isp_fe_ctx3_lmp_bayer: isp_fe-event-info@27 {
		irq-reg-space = "isp_fe";
		irq-src-reg = <0x0 0x500e8>;
		irq-reset-reg = <0x0 0x500e8>;
		irq-mask-reg = <0x0 0x500f0>;
		irq-overflow-reg = <0x0 0x500ec>;

		irq-events =
			<LWIS_PLATFORM_EVENT_ID_ISP_FE_CTX3_REGISTER_UPDATE>,
			<LWIS_PLATFORM_EVENT_ID_ISP_FE_CTX3_EOF>,
			<LWIS_PLATFORM_EVENT_ID_ISP_FE_CTX3_END_OF_BATCH>,
			<LWIS_PLATFORM_EVENT_ID_ISP_FE_CTX3_FE_LMP_ERROR>,
			<LWIS_PLATFORM_EVENT_ID_ISP_FE_CTX3_CDAF_PRIMARY>,
			<LWIS_PLATFORM_EVENT_ID_ISP_FE_CTX3_CDAF_WINDOWS>,
			<LWIS_PLATFORM_EVENT_ID_ISP_FE_CTX3_PRE_LSC_AE_STATS>,
			<LWIS_PLATFORM_EVENT_ID_ISP_FE_CTX3_AWB_STATS>,
			<LWIS_PLATFORM_EVENT_ID_ISP_FE_CTX3_LSC_STATS>,
			<LWIS_PLATFORM_EVENT_ID_ISP_FE_CTX3_FLICKER_STATS>,
			<LWIS_PLATFORM_EVENT_ID_ISP_FE_CTX3_HISTOGRAM0>,
			<LWIS_PLATFORM_EVENT_ID_ISP_FE_CTX3_HISTOGRAM1>,
			<LWIS_PLATFORM_EVENT_ID_ISP_FE_CTX3_HISTOGRAM2>,
			<LWIS_PLATFORM_EVENT_ID_ISP_FE_CTX3_POST_LSC_AE_STATS>,
			<LWIS_PLATFORM_EVENT_ID_ISP_FE_CTX3_MOTION_METERING>,
			<LWIS_PLATFORM_EVENT_ID_ISP_FE_CTX3_BAYER0_WDMA>,
			<LWIS_PLATFORM_EVENT_ID_ISP_FE_CTX3_BAYER1_WDMA>,
			<LWIS_PLATFORM_EVENT_ID_ISP_FE_CTX3_LINEAR_RGB_OUTPUT>,
			<LWIS_PLATFORM_EVENT_ID_ISP_FE_CTX3_ML_OUTPUT0>,
			<LWIS_PLATFORM_EVENT_ID_ISP_FE_CTX3_ML_OUTPUT1>,
			<LWIS_PLATFORM_EVENT_ID_ISP_FE_CTX3_ML_OUTPUT2>,
			<LWIS_PLATFORM_EVENT_ID_ISP_FE_CTX3_TNR_PYRAMID>,
			<LWIS_PLATFORM_EVENT_ID_ISP_FE_CTX3_MERGE1>,
			<LWIS_PLATFORM_EVENT_ID_ISP_FE_CTX3_MERGE2>,
			<LWIS_PLATFORM_EVENT_ID_ISP_FE_CTX3_MERGE3>,
			<LWIS_PLATFORM_EVENT_ID_ISP_FE_CTX3_MERGE4>,
			<LWIS_PLATFORM_EVENT_ID_ISP_FE_CTX3_MERGE5>,
			<LWIS_PLATFORM_EVENT_ID_ISP_FE_CTX3_MERGE6>,
			<LWIS_PLATFORM_EVENT_ID_ISP_FE_CTX3_LMP_BUS_ERROR>,
			<LWIS_PLATFORM_EVENT_ID_ISP_FE_CTX3_SOF>;
		int-reg-bits =
			<ISP_FE_LMP_BAYER_CTX3_REGISTER_UPDATE>,
			<ISP_FE_LMP_BAYER_CTX3_EOF>,
			<ISP_FE_LMP_BAYER_CTX3_END_OF_BATCH>,
			<ISP_FE_LMP_BAYER_CTX3_FE_LMP_ERROR>,
			<ISP_FE_LMP_BAYER_CTX3_CDAF_PRIMARY>,
			<ISP_FE_LMP_BAYER_CTX3_CDAF_WINDOWS>,
			<ISP_FE_LMP_BAYER_CTX3_PRE_LSC_AE_STATS>,
			<ISP_FE_LMP_BAYER_CTX3_AWB_STATS>,
			<ISP_FE_LMP_BAYER_CTX3_LSC_STATS>,
			<ISP_FE_LMP_BAYER_CTX3_FLICKER_STATS>,
			<ISP_FE_LMP_BAYER_CTX3_HISTOGRAM0>,
			<ISP_FE_LMP_BAYER_CTX3_HISTOGRAM1>,
			<ISP_FE_LMP_BAYER_CTX3_HISTOGRAM2>,
			<ISP_FE_LMP_BAYER_CTX3_POST_LSC_AE_STATS>,
			<ISP_FE_LMP_BAYER_CTX3_MOTION_METERING>,
			<ISP_FE_LMP_BAYER_CTX3_BAYER0_WDMA>,
			<ISP_FE_LMP_BAYER_CTX3_BAYER1_WDMA>,
			<ISP_FE_LMP_BAYER_CTX3_LINEAR_RGB_OUTPUT>,
			<ISP_FE_LMP_BAYER_CTX3_ML_OUTPUT0>,
			<ISP_FE_LMP_BAYER_CTX3_ML_OUTPUT1>,
			<ISP_FE_LMP_BAYER_CTX3_ML_OUTPUT2>,
			<ISP_FE_LMP_BAYER_CTX3_TNR_PYRAMID>,
			<ISP_FE_LMP_BAYER_CTX3_MERGE1>,
			<ISP_FE_LMP_BAYER_CTX3_MERGE2>,
			<ISP_FE_LMP_BAYER_CTX3_MERGE3>,
			<ISP_FE_LMP_BAYER_CTX3_MERGE4>,
			<ISP_FE_LMP_BAYER_CTX3_MERGE5>,
			<ISP_FE_LMP_BAYER_CTX3_MERGE6>,
			<ISP_FE_LMP_BAYER_CTX3_LMP_BUS_ERROR>,
			<ISP_FE_LMP_BAYER_CTX3_SOF>;
	};
	isp_fe_ctx4_lmp_bayer: isp_fe-event-info@28 {
		irq-reg-space = "isp_fe";
		irq-src-reg = <0x0 0x50118>;
		irq-reset-reg = <0x0 0x50118>;
		irq-mask-reg = <0x0 0x50120>;
		irq-overflow-reg = <0x0 0x5011c>;

		irq-events =
			<LWIS_PLATFORM_EVENT_ID_ISP_FE_CTX4_REGISTER_UPDATE>,
			<LWIS_PLATFORM_EVENT_ID_ISP_FE_CTX4_EOF>,
			<LWIS_PLATFORM_EVENT_ID_ISP_FE_CTX4_END_OF_BATCH>,
			<LWIS_PLATFORM_EVENT_ID_ISP_FE_CTX4_FE_LMP_ERROR>,
			<LWIS_PLATFORM_EVENT_ID_ISP_FE_CTX4_CDAF_PRIMARY>,
			<LWIS_PLATFORM_EVENT_ID_ISP_FE_CTX4_CDAF_WINDOWS>,
			<LWIS_PLATFORM_EVENT_ID_ISP_FE_CTX4_PRE_LSC_AE_STATS>,
			<LWIS_PLATFORM_EVENT_ID_ISP_FE_CTX4_AWB_STATS>,
			<LWIS_PLATFORM_EVENT_ID_ISP_FE_CTX4_LSC_STATS>,
			<LWIS_PLATFORM_EVENT_ID_ISP_FE_CTX4_FLICKER_STATS>,
			<LWIS_PLATFORM_EVENT_ID_ISP_FE_CTX4_HISTOGRAM0>,
			<LWIS_PLATFORM_EVENT_ID_ISP_FE_CTX4_HISTOGRAM1>,
			<LWIS_PLATFORM_EVENT_ID_ISP_FE_CTX4_HISTOGRAM2>,
			<LWIS_PLATFORM_EVENT_ID_ISP_FE_CTX4_POST_LSC_AE_STATS>,
			<LWIS_PLATFORM_EVENT_ID_ISP_FE_CTX4_MOTION_METERING>,
			<LWIS_PLATFORM_EVENT_ID_ISP_FE_CTX4_BAYER0_WDMA>,
			<LWIS_PLATFORM_EVENT_ID_ISP_FE_CTX4_BAYER1_WDMA>,
			<LWIS_PLATFORM_EVENT_ID_ISP_FE_CTX4_LINEAR_RGB_OUTPUT>,
			<LWIS_PLATFORM_EVENT_ID_ISP_FE_CTX4_ML_OUTPUT0>,
			<LWIS_PLATFORM_EVENT_ID_ISP_FE_CTX4_ML_OUTPUT1>,
			<LWIS_PLATFORM_EVENT_ID_ISP_FE_CTX4_ML_OUTPUT2>,
			<LWIS_PLATFORM_EVENT_ID_ISP_FE_CTX4_TNR_PYRAMID>,
			<LWIS_PLATFORM_EVENT_ID_ISP_FE_CTX4_MERGE1>,
			<LWIS_PLATFORM_EVENT_ID_ISP_FE_CTX4_MERGE2>,
			<LWIS_PLATFORM_EVENT_ID_ISP_FE_CTX4_MERGE3>,
			<LWIS_PLATFORM_EVENT_ID_ISP_FE_CTX4_MERGE4>,
			<LWIS_PLATFORM_EVENT_ID_ISP_FE_CTX4_MERGE5>,
			<LWIS_PLATFORM_EVENT_ID_ISP_FE_CTX4_MERGE6>,
			<LWIS_PLATFORM_EVENT_ID_ISP_FE_CTX4_LMP_BUS_ERROR>,
			<LWIS_PLATFORM_EVENT_ID_ISP_FE_CTX4_SOF>;
		int-reg-bits =
			<ISP_FE_LMP_BAYER_CTX4_REGISTER_UPDATE>,
			<ISP_FE_LMP_BAYER_CTX4_EOF>,
			<ISP_FE_LMP_BAYER_CTX4_END_OF_BATCH>,
			<ISP_FE_LMP_BAYER_CTX4_FE_LMP_ERROR>,
			<ISP_FE_LMP_BAYER_CTX4_CDAF_PRIMARY>,
			<ISP_FE_LMP_BAYER_CTX4_CDAF_WINDOWS>,
			<ISP_FE_LMP_BAYER_CTX4_PRE_LSC_AE_STATS>,
			<ISP_FE_LMP_BAYER_CTX4_AWB_STATS>,
			<ISP_FE_LMP_BAYER_CTX4_LSC_STATS>,
			<ISP_FE_LMP_BAYER_CTX4_FLICKER_STATS>,
			<ISP_FE_LMP_BAYER_CTX4_HISTOGRAM0>,
			<ISP_FE_LMP_BAYER_CTX4_HISTOGRAM1>,
			<ISP_FE_LMP_BAYER_CTX4_HISTOGRAM2>,
			<ISP_FE_LMP_BAYER_CTX4_POST_LSC_AE_STATS>,
			<ISP_FE_LMP_BAYER_CTX4_MOTION_METERING>,
			<ISP_FE_LMP_BAYER_CTX4_BAYER0_WDMA>,
			<ISP_FE_LMP_BAYER_CTX4_BAYER1_WDMA>,
			<ISP_FE_LMP_BAYER_CTX4_LINEAR_RGB_OUTPUT>,
			<ISP_FE_LMP_BAYER_CTX4_ML_OUTPUT0>,
			<ISP_FE_LMP_BAYER_CTX4_ML_OUTPUT1>,
			<ISP_FE_LMP_BAYER_CTX4_ML_OUTPUT2>,
			<ISP_FE_LMP_BAYER_CTX4_TNR_PYRAMID>,
			<ISP_FE_LMP_BAYER_CTX4_MERGE1>,
			<ISP_FE_LMP_BAYER_CTX4_MERGE2>,
			<ISP_FE_LMP_BAYER_CTX4_MERGE3>,
			<ISP_FE_LMP_BAYER_CTX4_MERGE4>,
			<ISP_FE_LMP_BAYER_CTX4_MERGE5>,
			<ISP_FE_LMP_BAYER_CTX4_MERGE6>,
			<ISP_FE_LMP_BAYER_CTX4_LMP_BUS_ERROR>,
			<ISP_FE_LMP_BAYER_CTX4_SOF>;
	};
	/* LMP pdaf pipeline interrupt event definitions */
	isp_fe_ctx0_lmp_pdaf: isp_fe-event-info@29 {
		irq-reg-space = "isp_fe";
		irq-src-reg = <0x0 0x50148>;
		irq-reset-reg = <0x0 0x50148>;
		irq-mask-reg = <0x0 0x50150>;
		irq-overflow-reg = <0x0 0x5014c>;

		irq-events =
			<LWIS_PLATFORM_EVENT_ID_ISP_FE_CTX0_SOF>,
			<LWIS_PLATFORM_EVENT_ID_ISP_FE_CTX0_EOF>,
			<LWIS_PLATFORM_EVENT_ID_ISP_FE_CTX0_END_OF_BATCH>,
			<LWIS_PLATFORM_EVENT_ID_ISP_FE_CTX0_EARLY>,
			<LWIS_PLATFORM_EVENT_ID_ISP_FE_CTX0_REGISTER_UPDATE>,
			<LWIS_PLATFORM_EVENT_ID_ISP_FE_CTX0_ABORT_START>,
			<LWIS_PLATFORM_EVENT_ID_ISP_FE_CTX0_ABORT_DMA_COMPLETE>,
			<LWIS_PLATFORM_EVENT_ID_ISP_FE_CTX0_ABORT_DONE>,
			<LWIS_PLATFORM_EVENT_ID_ISP_FE_CTX0_ERROR>,
			<LWIS_PLATFORM_EVENT_ID_ISP_FE_CTX0_BUS_ERROR>;
		int-reg-bits =
			<ISP_FE_LMP_PDAF_CTX0_SOF>,
			<ISP_FE_LMP_PDAF_CTX0_EOF>,
			<ISP_FE_LMP_PDAF_CTX0_END_OF_BATCH>,
			<ISP_FE_LMP_PDAF_CTX0_EARLY>,
			<ISP_FE_LMP_PDAF_CTX0_REGISTER_UPDATE>,
			<ISP_FE_LMP_PDAF_CTX0_ABORT_START>,
			<ISP_FE_LMP_PDAF_CTX0_ABORT_DMA_COMPLETE>,
			<ISP_FE_LMP_PDAF_CTX0_ABORT_DONE>,
			<ISP_FE_LMP_PDAF_CTX0_ERROR>,
			<ISP_FE_LMP_PDAF_CTX0_BUS_ERROR>;
	};
	isp_fe_ctx1_lmp_pdaf: isp_fe-event-info@30 {
		irq-reg-space = "isp_fe";
		irq-src-reg = <0x0 0x50160>;
		irq-reset-reg = <0x0 0x50160>;
		irq-mask-reg = <0x0 0x50168>;
		irq-overflow-reg = <0x0 0x50164>;

		irq-events =
			<LWIS_PLATFORM_EVENT_ID_ISP_FE_CTX1_SOF>,
			<LWIS_PLATFORM_EVENT_ID_ISP_FE_CTX1_EOF>,
			<LWIS_PLATFORM_EVENT_ID_ISP_FE_CTX1_END_OF_BATCH>,
			<LWIS_PLATFORM_EVENT_ID_ISP_FE_CTX1_EARLY>,
			<LWIS_PLATFORM_EVENT_ID_ISP_FE_CTX1_REGISTER_UPDATE>,
			<LWIS_PLATFORM_EVENT_ID_ISP_FE_CTX1_ABORT_START>,
			<LWIS_PLATFORM_EVENT_ID_ISP_FE_CTX1_ABORT_DMA_COMPLETE>,
			<LWIS_PLATFORM_EVENT_ID_ISP_FE_CTX1_ABORT_DONE>,
			<LWIS_PLATFORM_EVENT_ID_ISP_FE_CTX1_ERROR>,
			<LWIS_PLATFORM_EVENT_ID_ISP_FE_CTX1_BUS_ERROR>;
		int-reg-bits =
			<ISP_FE_LMP_PDAF_CTX1_SOF>,
			<ISP_FE_LMP_PDAF_CTX1_EOF>,
			<ISP_FE_LMP_PDAF_CTX1_END_OF_BATCH>,
			<ISP_FE_LMP_PDAF_CTX1_EARLY>,
			<ISP_FE_LMP_PDAF_CTX1_REGISTER_UPDATE>,
			<ISP_FE_LMP_PDAF_CTX1_ABORT_START>,
			<ISP_FE_LMP_PDAF_CTX1_ABORT_DMA_COMPLETE>,
			<ISP_FE_LMP_PDAF_CTX1_ABORT_DONE>,
			<ISP_FE_LMP_PDAF_CTX1_ERROR>,
			<ISP_FE_LMP_PDAF_CTX1_BUS_ERROR>;
	};
	isp_fe_ctx2_lmp_pdaf: isp_fe-event-info@31 {
		irq-reg-space = "isp_fe";
		irq-src-reg = <0x0 0x50178>;
		irq-reset-reg = <0x0 0x50178>;
		irq-mask-reg = <0x0 0x50180>;
		irq-overflow-reg = <0x0 0x5017c>;

		irq-events =
			<LWIS_PLATFORM_EVENT_ID_ISP_FE_CTX2_SOF>,
			<LWIS_PLATFORM_EVENT_ID_ISP_FE_CTX2_EOF>,
			<LWIS_PLATFORM_EVENT_ID_ISP_FE_CTX2_END_OF_BATCH>,
			<LWIS_PLATFORM_EVENT_ID_ISP_FE_CTX2_EARLY>,
			<LWIS_PLATFORM_EVENT_ID_ISP_FE_CTX2_REGISTER_UPDATE>,
			<LWIS_PLATFORM_EVENT_ID_ISP_FE_CTX2_ABORT_START>,
			<LWIS_PLATFORM_EVENT_ID_ISP_FE_CTX2_ABORT_DMA_COMPLETE>,
			<LWIS_PLATFORM_EVENT_ID_ISP_FE_CTX2_ABORT_DONE>,
			<LWIS_PLATFORM_EVENT_ID_ISP_FE_CTX2_ERROR>,
			<LWIS_PLATFORM_EVENT_ID_ISP_FE_CTX2_BUS_ERROR>;
		int-reg-bits =
			<ISP_FE_LMP_PDAF_CTX2_SOF>,
			<ISP_FE_LMP_PDAF_CTX2_EOF>,
			<ISP_FE_LMP_PDAF_CTX2_END_OF_BATCH>,
			<ISP_FE_LMP_PDAF_CTX2_EARLY>,
			<ISP_FE_LMP_PDAF_CTX2_REGISTER_UPDATE>,
			<ISP_FE_LMP_PDAF_CTX2_ABORT_START>,
			<ISP_FE_LMP_PDAF_CTX2_ABORT_DMA_COMPLETE>,
			<ISP_FE_LMP_PDAF_CTX2_ABORT_DONE>,
			<ISP_FE_LMP_PDAF_CTX2_ERROR>,
			<ISP_FE_LMP_PDAF_CTX2_BUS_ERROR>;
	};
	isp_fe_ctx3_lmp_pdaf: isp_fe-event-info@32 {
		irq-reg-space = "isp_fe";
		irq-src-reg = <0x0 0x50190>;
		irq-reset-reg = <0x0 0x50190>;
		irq-mask-reg = <0x0 0x50198>;
		irq-overflow-reg = <0x0 0x50194>;

		irq-events =
			<LWIS_PLATFORM_EVENT_ID_ISP_FE_CTX3_SOF>,
			<LWIS_PLATFORM_EVENT_ID_ISP_FE_CTX3_EOF>,
			<LWIS_PLATFORM_EVENT_ID_ISP_FE_CTX3_END_OF_BATCH>,
			<LWIS_PLATFORM_EVENT_ID_ISP_FE_CTX3_EARLY>,
			<LWIS_PLATFORM_EVENT_ID_ISP_FE_CTX3_REGISTER_UPDATE>,
			<LWIS_PLATFORM_EVENT_ID_ISP_FE_CTX3_ABORT_START>,
			<LWIS_PLATFORM_EVENT_ID_ISP_FE_CTX3_ABORT_DMA_COMPLETE>,
			<LWIS_PLATFORM_EVENT_ID_ISP_FE_CTX3_ABORT_DONE>,
			<LWIS_PLATFORM_EVENT_ID_ISP_FE_CTX3_ERROR>,
			<LWIS_PLATFORM_EVENT_ID_ISP_FE_CTX3_BUS_ERROR>;
		int-reg-bits =
			<ISP_FE_LMP_PDAF_CTX3_SOF>,
			<ISP_FE_LMP_PDAF_CTX3_EOF>,
			<ISP_FE_LMP_PDAF_CTX3_END_OF_BATCH>,
			<ISP_FE_LMP_PDAF_CTX3_EARLY>,
			<ISP_FE_LMP_PDAF_CTX3_REGISTER_UPDATE>,
			<ISP_FE_LMP_PDAF_CTX3_ABORT_START>,
			<ISP_FE_LMP_PDAF_CTX3_ABORT_DMA_COMPLETE>,
			<ISP_FE_LMP_PDAF_CTX3_ABORT_DONE>,
			<ISP_FE_LMP_PDAF_CTX3_ERROR>,
			<ISP_FE_LMP_PDAF_CTX3_BUS_ERROR>;
	};
	/* LMP debug interrupt event definitions */
	isp_fe_lmp_debug: isp_fe-event-info@33 {
		irq-reg-space = "isp_fe";
		irq-src-reg = <0x0 0x501ac>;
		irq-reset-reg = <0x0 0x501ac>;
		irq-mask-reg = <0x0 0x501a8>;

		irq-events =
			<LWIS_PLATFORM_EVENT_ID_ISP_FE_HW_TIMEOUT>,
			<LWIS_PLATFORM_EVENT_ID_ISP_FE_HW_BUS_ERROR>,
			<LWIS_PLATFORM_EVENT_ID_ISP_FE_HW_AXI_READ_DATA_OVERFLOW>,
			<LWIS_PLATFORM_EVENT_ID_ISP_FE_HW_AXI_WRITE_DATA_UNDERFLOW>,
			<LWIS_PLATFORM_EVENT_ID_ISP_FE_HW_LUT_ILLEGAL_PROGRAMMING_NON_SEQ>,
			<LWIS_PLATFORM_EVENT_ID_ISP_FE_HW_LUT_ILLEGAL_PROGRAMMING_NON_ATOMIC>,
			<LWIS_PLATFORM_EVENT_ID_ISP_FE_HW_LUT_ILLEGAL_PROGRAMMING_PARTIAL_BAYER>,
			<LWIS_PLATFORM_EVENT_ID_ISP_FE_HW_LUT_ILLEGAL_PROGRAMMING_PARTIAL_PDAF0>,
			<LWIS_PLATFORM_EVENT_ID_ISP_FE_HW_LUT_ILLEGAL_PROGRAMMING_PARTIAL_PDAF1>,
			<LWIS_PLATFORM_EVENT_ID_ISP_FE_HW_LUT_ILLEGAL_PROGRAMMING_PARTIAL_PDAF2>,
			<LWIS_PLATFORM_EVENT_ID_ISP_FE_HW_LUT_ILLEGAL_PROGRAMMING_PARTIAL_PDAF3>,
			<LWIS_PLATFORM_EVENT_ID_ISP_FE_HW_UNDEFINED>;
		int-reg-bits =
			<ISP_FE_LMP_DEBUG_HW_TIMEOUT>,
			<ISP_FE_LMP_DEBUG_HW_BUS_ERROR>,
			<ISP_FE_LMP_DEBUG_HW_AXI_READ_DATA_OVERFLOW>,
			<ISP_FE_LMP_DEBUG_HW_AXI_WRITE_DATA_UNDERFLOW>,
			<ISP_FE_LMP_DEBUG_HW_LUT_ILLEGAL_PROGRAMMING_NON_SEQ>,
			<ISP_FE_LMP_DEBUG_HW_LUT_ILLEGAL_PROGRAMMING_NON_ATOMIC>,
			<ISP_FE_LMP_DEBUG_HW_LUT_ILLEGAL_PROGRAMMING_PARTIAL_BAYER>,
			<ISP_FE_LMP_DEBUG_HW_LUT_ILLEGAL_PROGRAMMING_PARTIAL_PDAF0>,
			<ISP_FE_LMP_DEBUG_HW_LUT_ILLEGAL_PROGRAMMING_PARTIAL_PDAF1>,
			<ISP_FE_LMP_DEBUG_HW_LUT_ILLEGAL_PROGRAMMING_PARTIAL_PDAF2>,
			<ISP_FE_LMP_DEBUG_HW_LUT_ILLEGAL_PROGRAMMING_PARTIAL_PDAF3>,
			<ISP_FE_LMP_DEBUG_HW_UNDEFINED>;
	};

}
